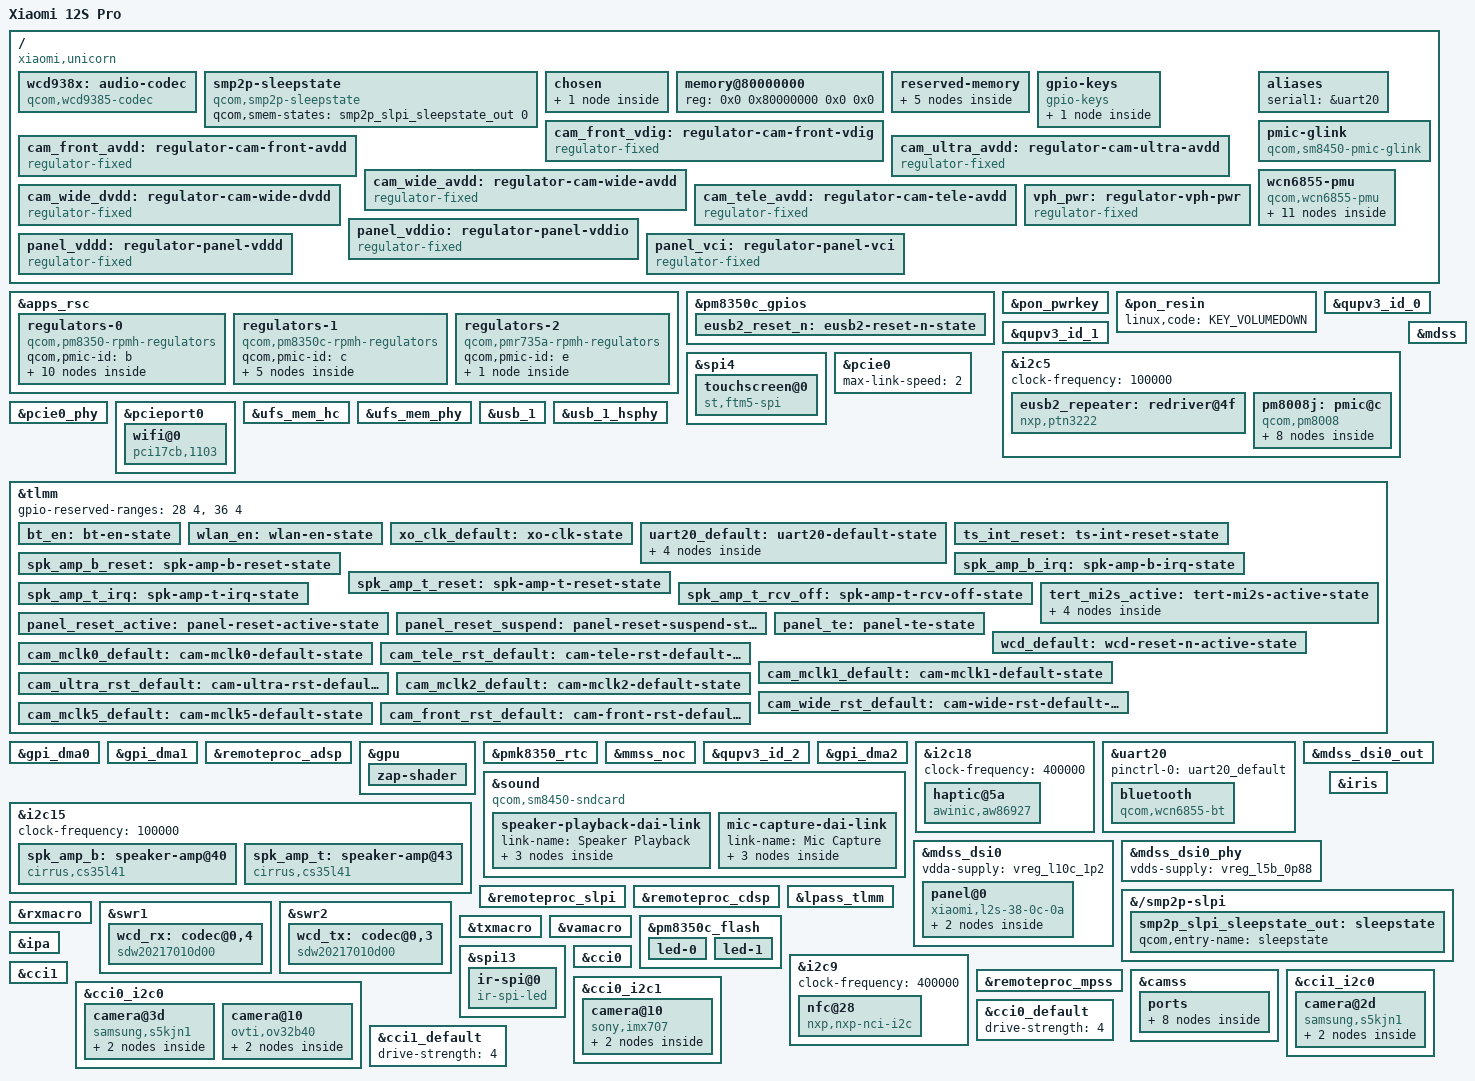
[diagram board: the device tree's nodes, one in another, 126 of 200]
// SPDX-License-Identifier: BSD-3-Clause
/*
 * Xiaomi 12S Pro (unicorn, 2206122SC, SM8475/cape)
 * Native mainline Linux DTS (UEFI EFI-stub + simplefb + USB gadget + UFS + Wi-Fi + Touch + Keys).
 */

/dts-v1/;

#include <dt-bindings/clock/qcom,sm8450-camcc.h>
#include <dt-bindings/firmware/qcom,scm.h>
#include <dt-bindings/media/video-interfaces.h>
#include <dt-bindings/gpio/gpio.h>
#include <dt-bindings/input/input.h>
#include <dt-bindings/leds/common.h>
#include <dt-bindings/interrupt-controller/arm-gic.h>
#include <dt-bindings/pinctrl/qcom,pmic-gpio.h>
#include <dt-bindings/regulator/qcom,rpmh-regulator.h>
#include <dt-bindings/sound/qcom,q6afe.h>
#include <dt-bindings/sound/qcom,q6dsp-lpass-ports.h>

#include "sm8475.dtsi"
#include "pm8350.dtsi"
#include "pm8350b.dtsi"
#include "pm8350c.dtsi"
#include "pm8450.dtsi"
#include "pmk8350.dtsi"
#include "pmr735a.dtsi"

/delete-node/ &adsp_mem;
/delete-node/ &rmtfs_mem;
/delete-node/ &xbl_ramdump_mem;
/delete-node/ &xbl_sc_mem;

/ {
	model = "Xiaomi 12S Pro";
	compatible = "xiaomi,unicorn", "qcom,cape-v2", "qcom,sm8475";
	chassis-type = "handset";

	wcd938x: audio-codec {
		compatible = "qcom,wcd9385-codec";

		pinctrl-0 = <&wcd_default>;
		pinctrl-names = "default";

		qcom,micbias1-microvolt = <2750000>;
		qcom,micbias2-microvolt = <2750000>;
		qcom,micbias3-microvolt = <2750000>;
		qcom,micbias4-microvolt = <2750000>;
		qcom,rx-device = <&wcd_rx>;
		qcom,tx-device = <&wcd_tx>;

		reset-gpios = <&tlmm 43 GPIO_ACTIVE_LOW>;

		vdd-buck-supply = <&vreg_s10b_1p8>;
		vdd-rxtx-supply = <&vreg_s10b_1p8>;
		vdd-io-supply = <&vreg_s10b_1p8>;
		vdd-mic-bias-supply = <&vreg_bob>;

		#sound-dai-cells = <1>;
	};

	smp2p-sleepstate {
		compatible = "qcom,smp2p-sleepstate";
		qcom,smem-states = <&smp2p_slpi_sleepstate_out 0>;
	};

	chosen {
		#address-cells = <2>;
		#size-cells = <2>;
		ranges;

		/* Continuous-splash / UEFI GOP framebuffer at 0xB8000000, 1440x3200 */
		framebuffer: framebuffer@b8000000 {
			compatible = "simple-framebuffer";
			reg = <0x0 0xb8000000 0x0 0x2b00000>;
			width = <1440>;
			height = <3200>;
			stride = <(1440 * 4)>;
			format = "a8r8g8b8";
			clocks = <&gcc GCC_DISP_HF_AXI_CLK>;
			power-domains = <&rpmhpd RPMHPD_MMCX>;
		};
	};

	memory@80000000 {
		device_type = "memory";
		reg = <0x0 0x80000000 0x0 0x0>;
	};

	reserved-memory {
		#address-cells = <2>;
		#size-cells = <2>;
		ranges;

		/* Remove sm8450.dtsi nodes that conflict with Unicorn's RAM/ADSP layout */
		/delete-node/ memory@80640000;
		/delete-node/ memory@85e00000;
		/delete-node/ memory@9fd00000;
		/delete-node/ memory@c0000000;

		xbl_ramdump_region@a6b80000 {
			reg = <0x0 0xa6b80000 0x0 0x280000>;
			no-map;
		};

		rmtfs_mem: memory@f8700000 {
			compatible = "qcom,rmtfs-mem";
			reg = <0x0 0xf8700000 0x0 0x280000>;
			no-map;

			qcom,client-id = <1>;
			qcom,vmid = <QCOM_SCM_VMID_MSS_MSA>;
		};

		adsp_mem: memory@9fd00000 {
			reg = <0x0 0x9fd00000 0x0 0x3100000>;
			no-map;
		};

		splash_mem: memory@b8000000 {
			reg = <0x0 0xb8000000 0x0 0x2b00000>;
			no-map;
		};

		ramoops@a7000000 {
			compatible = "ramoops";
			reg = <0x0 0xa7000000 0x0 0x400000>;
			console-size = <0x200000>;
			pmsg-size = <0x200000>;
		};
	};

	gpio-keys {
		compatible = "gpio-keys";

		key-volume-up {
			label = "Volume Up";
			gpios = <&pm8350c_gpios 6 GPIO_ACTIVE_LOW>;
			linux,code = <KEY_VOLUMEUP>;
			debounce-interval = <15>;
			linux,can-disable;
			wakeup-source;
		};
	};

	/* Front 32MP OV32B40 1.104 V VDIG, switched by TLMM 44 (vendor camera_front_vdig_ldo) */
	cam_front_vdig: regulator-cam-front-vdig {
		compatible = "regulator-fixed";
		regulator-name = "cam_front_vdig";
		regulator-min-microvolt = <1104000>;
		regulator-max-microvolt = <1104000>;
		gpio = <&tlmm 44 GPIO_ACTIVE_HIGH>;
		enable-active-high;
		startup-delay-us = <100>;
		vin-supply = <&vreg_s12b_1p25>;
	};

	/* Front 32MP OV32B40 2.8 V AVDD, switched by TLMM 64 (vendor camera_front_avdd_ldo) */
	cam_front_avdd: regulator-cam-front-avdd {
		compatible = "regulator-fixed";
		regulator-name = "cam_front_avdd";
		regulator-min-microvolt = <2800000>;
		regulator-max-microvolt = <2800000>;
		gpio = <&tlmm 64 GPIO_ACTIVE_HIGH>;
		enable-active-high;
		startup-delay-us = <100>;
		vin-supply = <&vreg_bob>;
	};

	/* Rear ultrawide 50MP S5KJN1 2.8 V AVDD, switched by TLMM 6 (vendor CAMERA_ULTRA_AVDD) */
	cam_ultra_avdd: regulator-cam-ultra-avdd {
		compatible = "regulator-fixed";
		regulator-name = "cam_ultra_avdd";
		regulator-min-microvolt = <2800000>;
		regulator-max-microvolt = <2800000>;
		gpio = <&tlmm 6 GPIO_ACTIVE_HIGH>;
		enable-active-high;
		startup-delay-us = <100>;
		vin-supply = <&vreg_bob>;
	};

	/* Rear main 50MP Sony IMX707 1.86 V AVDD2, switched by TLMM 70 (vendor camera_wide_avdd_ldo) */
	cam_wide_avdd: regulator-cam-wide-avdd {
		compatible = "regulator-fixed";
		regulator-name = "cam_wide_avdd";
		regulator-min-microvolt = <1860000>;
		regulator-max-microvolt = <1860000>;
		gpio = <&tlmm 70 GPIO_ACTIVE_HIGH>;
		enable-active-high;
		startup-delay-us = <100>;
		vin-supply = <&vreg_bob>;
	};

	/* Rear main 50MP Sony IMX707 1.25 V DVDD, switched by TLMM 2 (vendor camera_wide_dvdd_ldo) */
	cam_wide_dvdd: regulator-cam-wide-dvdd {
		compatible = "regulator-fixed";
		regulator-name = "cam_wide_dvdd";
		regulator-min-microvolt = <1250000>;
		regulator-max-microvolt = <1250000>;
		gpio = <&tlmm 2 GPIO_ACTIVE_HIGH>;
		enable-active-high;
		startup-delay-us = <100>;
		vin-supply = <&vreg_s12b_1p25>;
	};

	/* Rear telephoto 50MP S5KJN1 2.8 V AVDD, switched by TLMM 71 (vendor CAMERA_TELE_AVDD) */
	cam_tele_avdd: regulator-cam-tele-avdd {
		compatible = "regulator-fixed";
		regulator-name = "cam_tele_avdd";
		regulator-min-microvolt = <2800000>;
		regulator-max-microvolt = <2800000>;
		gpio = <&tlmm 71 GPIO_ACTIVE_HIGH>;
		enable-active-high;
		startup-delay-us = <100>;
		vin-supply = <&vreg_bob>;
	};

	vph_pwr: regulator-vph-pwr {
		compatible = "regulator-fixed";
		regulator-name = "vph_pwr";
		regulator-min-microvolt = <3700000>;
		regulator-max-microvolt = <3700000>;
		regulator-always-on;
		regulator-boot-on;
	};

	aliases {
		serial1 = &uart20;
	};

	pmic-glink {
		compatible = "qcom,sm8450-pmic-glink", "qcom,pmic-glink";
		#address-cells = <1>;
		#size-cells = <0>;
	};

	/* QCA6490 / WCN6855 PMU: WLAN_EN=80, BT_EN=81, SW_CTRL=82, XO_CLK=204 */
	wcn6855-pmu {
		compatible = "qcom,wcn6855-pmu";

		pinctrl-0 = <&bt_en>, <&wlan_en>, <&xo_clk_default>;
		pinctrl-names = "default";

		wlan-enable-gpios = <&tlmm 80 GPIO_ACTIVE_HIGH>;
		bt-enable-gpios = <&tlmm 81 GPIO_ACTIVE_HIGH>;
		swctrl-gpios = <&tlmm 82 GPIO_ACTIVE_HIGH>;
		xo-clk-gpios = <&tlmm 204 GPIO_ACTIVE_HIGH>;

		vddio-supply = <&vreg_s10b_1p8>;
		vddaon-supply = <&vreg_s11b_0p95>;
		vddpmu-supply = <&vreg_s12b_1p25>;
		vddpmumx-supply = <&vreg_s2e_0p5>;
		vddpmucx-supply = <&vreg_s11b_0p95>;
		vddrfa0p95-supply = <&vreg_s11b_0p95>;
		vddrfa1p3-supply = <&vreg_s12b_1p25>;
		vddrfa1p9-supply = <&vreg_s1c_1p86>;
		vddpcie1p3-supply = <&vreg_s12b_1p25>;
		vddpcie1p9-supply = <&vreg_s1c_1p86>;

		regulators {
			vreg_pmu_rfa_cmn_0p8: ldo0 {
				regulator-name = "vreg_pmu_rfa_cmn_0p8";
			};

			vreg_pmu_aon_0p8: ldo1 {
				regulator-name = "vreg_pmu_aon_0p8";
			};

			vreg_pmu_wlcx_0p8: ldo2 {
				regulator-name = "vreg_pmu_wlcx_0p8";
			};

			vreg_pmu_wlmx_0p8: ldo3 {
				regulator-name = "vreg_pmu_wlmx_0p8";
			};

			vreg_pmu_btcmx_0p8: ldo4 {
				regulator-name = "vreg_pmu_btcmx_0p8";
			};

			vreg_pmu_pcie_1p8: ldo5 {
				regulator-name = "vreg_pmu_pcie_1p8";
			};

			vreg_pmu_pcie_0p9: ldo6 {
				regulator-name = "vreg_pmu_pcie_0p9";
			};

			vreg_pmu_rfa_0p8: ldo7 {
				regulator-name = "vreg_pmu_rfa_0p8";
			};

			vreg_pmu_rfa_1p2: ldo8 {
				regulator-name = "vreg_pmu_rfa_1p2";
			};

			vreg_pmu_rfa_1p7: ldo9 {
				regulator-name = "vreg_pmu_rfa_1p7";
			};
		};
	};
};

&apps_rsc {
	regulators-0 {
		compatible = "qcom,pm8350-rpmh-regulators";
		qcom,pmic-id = "b";

		vreg_s10b_1p8: smps10 {
			regulator-name = "vreg_s10b_1p8";
			regulator-min-microvolt = <1800000>;
			regulator-max-microvolt = <1800000>;
		};

		vreg_s11b_0p95: smps11 {
			regulator-name = "vreg_s11b_0p95";
			regulator-min-microvolt = <952000>;
			regulator-max-microvolt = <1170000>;
		};

		vreg_s12b_1p25: smps12 {
			regulator-name = "vreg_s12b_1p25";
			regulator-min-microvolt = <1350000>;
			regulator-max-microvolt = <2040000>;
		};

		vreg_l1b_0p91: ldo1 {
			regulator-name = "vreg_l1b_0p91";
			regulator-min-microvolt = <912000>;
			regulator-max-microvolt = <920000>;
			regulator-initial-mode = <RPMH_REGULATOR_MODE_HPM>;
		};

		vreg_l2b_3p07: ldo2 {
			regulator-name = "vreg_l2b_3p07";
			regulator-min-microvolt = <3072000>;
			regulator-max-microvolt = <3300000>;
			regulator-initial-mode = <RPMH_REGULATOR_MODE_HPM>;
		};

		vreg_l3b_0p9: ldo3 {
			regulator-name = "vreg_l3b_0p9";
			regulator-min-microvolt = <904000>;
			regulator-max-microvolt = <970000>;
			regulator-initial-mode = <RPMH_REGULATOR_MODE_HPM>;
		};

		vreg_l5b_0p88: ldo5 {
			regulator-name = "vreg_l5b_0p88";
			regulator-min-microvolt = <880000>;
			regulator-max-microvolt = <958000>;
			regulator-initial-mode = <RPMH_REGULATOR_MODE_HPM>;
		};

		vreg_l6b_1p2: ldo6 {
			regulator-name = "vreg_l6b_1p2";
			regulator-min-microvolt = <1200000>;
			regulator-max-microvolt = <1216000>;
			regulator-initial-mode = <RPMH_REGULATOR_MODE_HPM>;
		};

		vreg_l7b_2p5: ldo7 {
			regulator-name = "vreg_l7b_2p5";
			regulator-min-microvolt = <2504000>;
			regulator-max-microvolt = <3544000>;
			regulator-initial-mode = <RPMH_REGULATOR_MODE_HPM>;
		};

		vreg_l9b_1p2: ldo9 {
			regulator-name = "vreg_l9b_1p2";
			regulator-min-microvolt = <1200000>;
			regulator-max-microvolt = <1304000>;
			regulator-initial-mode = <RPMH_REGULATOR_MODE_HPM>;
		};
	};

	regulators-1 {
		compatible = "qcom,pm8350c-rpmh-regulators";
		qcom,pmic-id = "c";

		/* All entries verified present in live unicorn cmd-db */
		vreg_bob: bob {
			regulator-name = "vreg_bob";
			regulator-min-microvolt = <3008000>;
			regulator-max-microvolt = <3960000>;
			regulator-initial-mode = <RPMH_REGULATOR_MODE_AUTO>;
		};

		vreg_s1c_1p86: smps1 {
			regulator-name = "vreg_s1c_1p86";
			regulator-min-microvolt = <1888000>;
			regulator-max-microvolt = <2016000>;
		};

		vreg_l2c_1p8: ldo2 {
			regulator-name = "vreg_l2c_1p8";
			regulator-min-microvolt = <1800000>;
			regulator-max-microvolt = <1984000>;
			regulator-initial-mode = <RPMH_REGULATOR_MODE_HPM>;
		};

		/* Unicorn stock DTB uses pm8350c ldo9 at 3.224 V for FTM5 avdd */
		vreg_l9c_2p96: ldo9 {
			regulator-name = "vreg_l9c_2p96";
			regulator-min-microvolt = <3224000>;
			regulator-max-microvolt = <3224000>;
			regulator-initial-mode = <RPMH_REGULATOR_MODE_HPM>;
		};

		vreg_l10c_1p2: ldo10 {
			regulator-name = "vreg_l10c_1p2";
			regulator-min-microvolt = <1200000>;
			regulator-max-microvolt = <1304000>;
			regulator-initial-mode = <RPMH_REGULATOR_MODE_HPM>;
		};
	};

	regulators-2 {
		compatible = "qcom,pmr735a-rpmh-regulators";
		qcom,pmic-id = "e";

		/* smpe2 verified present in live unicorn cmd-db */
		vreg_s2e_0p5: smps2 {
			regulator-name = "vreg_s2e_0p5";
			regulator-min-microvolt = <1012000>;
			regulator-max-microvolt = <1040000>;
		};
	};
};

&pm8350c_gpios {
	eusb2_reset_n: eusb2-reset-n-state {
		pins = "gpio7";
		function = PMIC_GPIO_FUNC_NORMAL;
		power-source = <1>;
		qcom,drive-strength = <PMIC_GPIO_STRENGTH_MED>;
		bias-disable;
		output-enable;
	};
};

&pon_pwrkey {
	status = "okay";
};

&pon_resin {
	linux,code = <KEY_VOLUMEDOWN>;
	status = "okay";
};

&qupv3_id_0 {
	status = "okay";
};

&qupv3_id_1 {
	status = "okay";
};

&i2c5 {
	clock-frequency = <100000>;
	status = "okay";

	eusb2_repeater: redriver@4f {
		compatible = "nxp,ptn3222";
		reg = <0x4f>;
		#phy-cells = <0>;

		vdd3v3-supply = <&vreg_l2b_3p07>;
		vdd1v8-supply = <&vreg_s10b_1p8>;

		reset-gpios = <&pm8350c_gpios 7 GPIO_ACTIVE_LOW>;
		pinctrl-0 = <&eusb2_reset_n>;
		pinctrl-names = "default";
	};
};

&spi4 {
	status = "okay";

	touchscreen@0 {
		compatible = "st,ftm5-spi";
		reg = <0>;
		spi-max-frequency = <12000000>;

		interrupts-extended = <&tlmm 21 IRQ_TYPE_LEVEL_LOW>;
		reset-gpios = <&tlmm 20 GPIO_ACTIVE_LOW>;

		vdd-supply = <&vreg_l2c_1p8>;
		avdd-supply = <&vreg_l9c_2p96>;

		/* 10x unicorn 1440x3200 panel resolution */
		touchscreen-size-x = <14400>;
		touchscreen-size-y = <32000>;

		pinctrl-0 = <&ts_int_reset>;
		pinctrl-names = "default";
	};
};

&pcie0 {
	max-link-speed = <2>;
	status = "okay";
};

&pcie0_phy {
	vdda-phy-supply = <&vreg_l5b_0p88>;
	vdda-pll-supply = <&vreg_l10c_1p2>;
	status = "okay";
};

&pcieport0 {
	wifi@0 {
		compatible = "pci17cb,1103";
		reg = <0x10000 0x0 0x0 0x0 0x0>;

		/* unicorn board-2.bin uses the default entry without variant suffix */
		vddrfacmn-supply = <&vreg_pmu_rfa_cmn_0p8>;
		vddaon-supply = <&vreg_pmu_aon_0p8>;
		vddwlcx-supply = <&vreg_pmu_wlcx_0p8>;
		vddwlmx-supply = <&vreg_pmu_wlmx_0p8>;
		vddpcie1p8-supply = <&vreg_pmu_pcie_1p8>;
		vddpcie0p9-supply = <&vreg_pmu_pcie_0p9>;
		vddrfa0p8-supply = <&vreg_pmu_rfa_0p8>;
		vddrfa1p2-supply = <&vreg_pmu_rfa_1p2>;
		vddrfa1p8-supply = <&vreg_pmu_rfa_1p7>;
	};
};

&ufs_mem_hc {
	reset-gpios = <&tlmm 210 GPIO_ACTIVE_LOW>;
	lanes-per-direction = <2>;

	vcc-supply = <&vreg_l7b_2p5>;
	vcc-max-microamp = <1100000>;
	vccq-supply = <&vreg_l9b_1p2>;
	vccq-max-microamp = <1200000>;

	status = "okay";
};

&ufs_mem_phy {
	vdda-phy-supply = <&vreg_l5b_0p88>;
	vdda-pll-supply = <&vreg_l10c_1p2>;
	status = "okay";
};

&usb_1 {
	dr_mode = "peripheral";
	maximum-speed = "high-speed";
	qcom,select-utmi-as-pipe-clk;

	phys = <&usb_1_hsphy>;
	phy-names = "usb2-phy";

	status = "okay";
};

&usb_1_hsphy {
	vdd-supply = <&vreg_l5b_0p88>;
	vdda12-supply = <&vreg_l10c_1p2>;

	phys = <&eusb2_repeater>;

	status = "okay";
};

&tlmm {
	/* Secure-world owned, per qcom,gpios-reserved in unicorn stock DTB */
	gpio-reserved-ranges = <28 4>, <36 4>;

	bt_en: bt-en-state {
		pins = "gpio81";
		function = "gpio";
		drive-strength = <16>;
		output-low;
		bias-pull-down;
	};

	wlan_en: wlan-en-state {
		pins = "gpio80";
		function = "gpio";
		drive-strength = <16>;
		output-low;
		bias-pull-down;
	};

	xo_clk_default: xo-clk-state {
		pins = "gpio204";
		function = "gpio";
		drive-strength = <16>;
		output-low;
		bias-pull-down;
	};

	uart20_default: uart20-default-state {
		cts-pins {
			pins = "gpio76";
			function = "qup20";
			drive-strength = <2>;
			bias-disable;
		};

		rts-pins {
			pins = "gpio77";
			function = "qup20";
			drive-strength = <2>;
			bias-pull-down;
		};

		tx-pins {
			pins = "gpio78";
			function = "qup20";
			drive-strength = <2>;
			bias-pull-up;
		};

		rx-pins {
			pins = "gpio79";
			function = "qup20";
			drive-strength = <2>;
			bias-disable;
		};
	};

	ts_int_reset: ts-int-reset-state {
		pins = "gpio20", "gpio21";
		function = "gpio";
		drive-strength = <8>;
		bias-pull-up;
	};
};

&gpi_dma0 {
	status = "okay";
};

&gpi_dma1 {
	status = "okay";
};

&remoteproc_adsp {
	firmware-name = "qcom/sm8475/xiaomi/unicorn/adsp.mbn";
	status = "okay";
};

&gpu {
	status = "okay";

	zap-shader {
		firmware-name = "qcom/sm8475/xiaomi/unicorn/a730_zap.mbn";
	};
};

&pmk8350_rtc {
	status = "okay";
};

/*
 * Keep ABL continuous-splash display-to-DDR bandwidth (RPMh BCM MM0/MM1)
 * active while simpledrm drives 0xB8000000: if mmss_noc probes with all
 * multimedia consumers disabled, icc_sync_state() drops MM1 to 0 at t=10s
 * and freezes the command-mode OLED panel on the last boot-console frame.
 */
&mmss_noc {
	status = "okay";
};

&qupv3_id_2 {
	status = "okay";
};

&gpi_dma2 {
	status = "okay";
};

&i2c18 {
	clock-frequency = <400000>;
	status = "okay";

	haptic@5a {
		compatible = "awinic,aw86927";
		reg = <0x5a>;
		reset-gpios = <&tlmm 89 GPIO_ACTIVE_LOW>;
		interrupts-extended = <&tlmm 90 IRQ_TYPE_EDGE_RISING>;
	};
};

&uart20 {
	pinctrl-0 = <&uart20_default>;
	pinctrl-names = "default";
	status = "okay";

	bluetooth {
		compatible = "qcom,wcn6855-bt";

		vddrfacmn-supply = <&vreg_pmu_rfa_cmn_0p8>;
		vddaon-supply = <&vreg_pmu_aon_0p8>;
		vddwlcx-supply = <&vreg_pmu_wlcx_0p8>;
		vddwlmx-supply = <&vreg_pmu_wlmx_0p8>;
		vddbtcmx-supply = <&vreg_pmu_btcmx_0p8>;
		vddrfa0p8-supply = <&vreg_pmu_rfa_0p8>;
		vddrfa1p2-supply = <&vreg_pmu_rfa_1p2>;
		vddrfa1p7-supply = <&vreg_pmu_rfa_1p7>;

		firmware-name = "unicorn/hpnv21", "unicorn/hpbtfw21.tlv";
		local-bd-address = [ ac 78 56 34 12 02 ];
	};
};

/* Stereo loudspeaker amplifiers: QUP SE15 (0x880000) -> CS35L41 @0x40 (bottom) & @0x43 (top) */
&i2c15 {
	clock-frequency = <100000>;
	status = "okay";

	spk_amp_b: speaker-amp@40 {
		compatible = "cirrus,cs35l41";
		reg = <0x40>;
		interrupts-extended = <&tlmm 117 IRQ_TYPE_LEVEL_LOW>;
		reset-gpios = <&tlmm 120 GPIO_ACTIVE_HIGH>;
		pinctrl-0 = <&spk_amp_b_reset>, <&spk_amp_b_irq>;
		pinctrl-names = "default";
		cirrus,boost-type = <0>;
		cirrus,boost-peak-milliamp = <4000>;
		cirrus,boost-ind-nanohenry = <1000>;
		cirrus,boost-cap-microfarad = <15>;
		cirrus,asp-sdout-hiz = <3>;
		cirrus,gpio2-src-select = <4>;
		cirrus,gpio2-output-enable;
		cirrus,subsystem-id = "unicorn";
		sound-name-prefix = "B";
		#sound-dai-cells = <1>;
	};

	spk_amp_t: speaker-amp@43 {
		compatible = "cirrus,cs35l41";
		reg = <0x43>;
		interrupts-extended = <&tlmm 88 IRQ_TYPE_LEVEL_LOW>;
		reset-gpios = <&tlmm 1 GPIO_ACTIVE_HIGH>;
		pinctrl-0 = <&spk_amp_t_reset>, <&spk_amp_t_irq>, <&spk_amp_t_rcv_off>;
		pinctrl-names = "default";
		cirrus,boost-type = <0>;
		cirrus,boost-peak-milliamp = <4000>;
		cirrus,boost-ind-nanohenry = <1000>;
		cirrus,boost-cap-microfarad = <15>;
		cirrus,asp-sdout-hiz = <3>;
		cirrus,gpio2-src-select = <4>;
		cirrus,gpio2-output-enable;
		cirrus,subsystem-id = "unicorn";
		sound-name-prefix = "T";
		#sound-dai-cells = <1>;
	};
};

&sound {
	compatible = "qcom,sm8450-sndcard";
	model = "XIAOMI-UNICORN";

	pinctrl-0 = <&tert_mi2s_active>;
	pinctrl-names = "default";

	clocks = <&q6prmcc LPASS_CLK_ID_TER_TDM_IBIT LPASS_CLK_ATTRIBUTE_INVERT_COUPLE_NO>;
	clock-names = "tertiary-mi2s";

	audio-routing = "AMIC1", "MIC BIAS1",
			"AMIC5", "MIC BIAS4",
			"TX SWR_INPUT0", "ADC1_OUTPUT",
			"TX SWR_INPUT1", "ADC4_OUTPUT";

	speaker-playback-dai-link {
		link-name = "Speaker Playback";

		cpu {
			sound-dai = <&q6apmbedai TERTIARY_TDM_RX_0>;
		};

		codec {
			sound-dai = <&spk_amp_t 0>, <&spk_amp_b 0>;
		};

		platform {
			sound-dai = <&q6apm>;
		};
	};

	mic-capture-dai-link {
		link-name = "Mic Capture";

		cpu {
			sound-dai = <&q6apmbedai TX_CODEC_DMA_TX_3>;
		};

		codec {
			sound-dai = <&wcd938x 1>, <&swr2 0>, <&txmacro 0>;
		};

		platform {
			sound-dai = <&q6apm>;
		};
	};
};

&tlmm {
	spk_amp_b_reset: spk-amp-b-reset-state {
		pins = "gpio120";
		function = "gpio";
		drive-strength = <16>;
		bias-disable;
	};

	spk_amp_b_irq: spk-amp-b-irq-state {
		pins = "gpio117";
		function = "gpio";
		drive-strength = <2>;
		bias-pull-up;
	};

	spk_amp_t_reset: spk-amp-t-reset-state {
		pins = "gpio1";
		function = "gpio";
		drive-strength = <16>;
		bias-disable;
	};

	spk_amp_t_irq: spk-amp-t-irq-state {
		pins = "gpio88";
		function = "gpio";
		drive-strength = <2>;
		bias-pull-up;
	};

	spk_amp_t_rcv_off: spk-amp-t-rcv-off-state {
		pins = "gpio52";
		function = "gpio";
		drive-strength = <2>;
		bias-disable;
		output-low;
	};

	tert_mi2s_active: tert-mi2s-active-state {
		sck-pins {
			pins = "gpio121";
			function = "mi2s2_sck";
			drive-strength = <8>;
			bias-disable;
		};

		data0-pins {
			pins = "gpio122";
			function = "mi2s2_data0";
			drive-strength = <8>;
			bias-disable;
		};

		ws-pins {
			pins = "gpio123";
			function = "mi2s2_ws";
			drive-strength = <8>;
			bias-disable;
		};

		data1-pins {
			pins = "gpio124";
			function = "mi2s2_data1";
			drive-strength = <8>;
			bias-disable;
		};
	};
};

/ {
	panel_vddio: regulator-panel-vddio {
		compatible = "regulator-fixed";
		regulator-name = "display_panel_vddio";
		regulator-min-microvolt = <1800000>;
		regulator-max-microvolt = <1800000>;
		gpio = <&tlmm 74 GPIO_ACTIVE_HIGH>;
		enable-active-high;
		regulator-boot-on;
	};

	panel_vddd: regulator-panel-vddd {
		compatible = "regulator-fixed";
		regulator-name = "display_panel_vddd";
		regulator-min-microvolt = <1500000>;
		regulator-max-microvolt = <1500000>;
		gpio = <&tlmm 25 GPIO_ACTIVE_HIGH>;
		enable-active-high;
		regulator-boot-on;
	};

	panel_vci: regulator-panel-vci {
		compatible = "regulator-fixed";
		regulator-name = "display_panel_vci";
		regulator-min-microvolt = <3000000>;
		regulator-max-microvolt = <3000000>;
		gpio = <&tlmm 75 GPIO_ACTIVE_HIGH>;
		enable-active-high;
		regulator-boot-on;
	};
};

&mdss {
	status = "okay";
};

&mdss_dsi0 {
	vdda-supply = <&vreg_l10c_1p2>;
	status = "okay";

	panel@0 {
		compatible = "xiaomi,l2s-38-0c-0a";
		reg = <0>;

		reset-gpios = <&tlmm 0 GPIO_ACTIVE_LOW>;
		vddio-supply = <&panel_vddio>;
		vddd-supply = <&panel_vddd>;
		vci-supply = <&panel_vci>;

		pinctrl-0 = <&panel_reset_active>, <&panel_te>;
		pinctrl-1 = <&panel_reset_suspend>, <&panel_te>;
		pinctrl-names = "default", "sleep";

		port {
			panel_in: endpoint {
				remote-endpoint = <&mdss_dsi0_out>;
			};
		};
	};
};

&mdss_dsi0_out {
	data-lanes = <0 1 2 3>;
	remote-endpoint = <&panel_in>;
};

&mdss_dsi0_phy {
	vdds-supply = <&vreg_l5b_0p88>;
	status = "okay";
};

&tlmm {
	panel_reset_active: panel-reset-active-state {
		pins = "gpio0";
		function = "gpio";
		drive-strength = <8>;
		bias-disable;
	};

	panel_reset_suspend: panel-reset-suspend-state {
		pins = "gpio0";
		function = "gpio";
		drive-strength = <2>;
		bias-pull-down;
	};

	panel_te: panel-te-state {
		pins = "gpio86";
		function = "mdp_vsync";
		drive-strength = <2>;
		bias-pull-down;
	};
};


/* === Wave 2 Hardware Bring-up === */

/* Qualcomm IRIS2 Hardware Video Decoder (H.264/HEVC/VP9 4K60) */
&iris {
	firmware-name = "qcom/sm8475/xiaomi/unicorn/vpu20_4v.mbn";
	status = "okay";
};

/* Sensor Low Power Island DSP (SLPI) + AP wake/sleep state */
&remoteproc_slpi {
	firmware-name = "qcom/sm8475/xiaomi/unicorn/slpi.mbn";
	status = "okay";
};

&{/smp2p-slpi} {
	smp2p_slpi_sleepstate_out: sleepstate {
		qcom,entry-name = "sleepstate";
		#qcom,smem-state-cells = <1>;
	};
};

/* Hexagon Compute/AI DSP (CDSP) */
&remoteproc_cdsp {
	firmware-name = "qcom/sm8475/xiaomi/unicorn/cdsp.mbn";
	status = "okay";
};

/* Built-in Dual Microphones (WCD9385 over SoundWire + LPASS TX/RX/VA Macros) */
&lpass_tlmm {
	status = "okay";
};

&rxmacro {
	status = "okay";
};

&swr1 {
	status = "okay";

	wcd_rx: codec@0,4 {
		compatible = "sdw20217010d00";
		reg = <0 4>;
		qcom,rx-port-mapping = <1 2 3 4 5>;
	};
};

&swr2 {
	status = "okay";

	wcd_tx: codec@0,3 {
		compatible = "sdw20217010d00";
		reg = <0 3>;
		qcom,tx-port-mapping = <1 1 2 3>;
	};
};

&txmacro {
	status = "okay";
};

&vamacro {
	status = "okay";
};

/* Rear Dual-LED Camera Flashlight / Torch (PM8350C Flash) */
&pm8350c_flash {
	status = "okay";

	led-0 {
		function = LED_FUNCTION_FLASH;
		color = <LED_COLOR_ID_WHITE>;
		led-sources = <1>, <4>;
		led-max-microamp = <500000>;
		flash-max-microamp = <1500000>;
		flash-max-timeout-us = <1280000>;
	};

	led-1 {
		function = LED_FUNCTION_FLASH;
		color = <LED_COLOR_ID_AMBER>;
		led-sources = <2>, <3>;
		led-max-microamp = <500000>;
		flash-max-microamp = <1500000>;
		flash-max-timeout-us = <1280000>;
	};
};

/* NXP SN110T NFC Controller on QUP SE9 I2C (@0x28) */
&i2c9 {
	clock-frequency = <400000>;
	status = "okay";

	nfc@28 {
		compatible = "nxp,nxp-nci-i2c";
		reg = <0x28>;
		enable-gpios = <&tlmm 34 GPIO_ACTIVE_HIGH>;
		firmware-gpios = <&tlmm 45 GPIO_ACTIVE_HIGH>;
		interrupts-extended = <&tlmm 46 IRQ_TYPE_EDGE_RISING>;
	};
};

/* Xiaomi Infrared Blaster on QUP SE13 SPI (ir-spi-led -> /dev/lirc0) */
&spi13 {
	status = "okay";

	ir-spi@0 {
		compatible = "ir-spi-led";
		reg = <0>;
		spi-max-frequency = <19200000>;
	};
};

&tlmm {
	wcd_default: wcd-reset-n-active-state {
		pins = "gpio43";
		function = "gpio";
		drive-strength = <16>;
		bias-disable;
		output-low;
	};
};


/* === Wave 3 Hardware Bring-up: 5G Modem + IPA v5.1 + CAMSS + PM8008 + 50MP S5KJN1 === */

&ipa {
	qcom,gsi-loader = "self";
	memory-region = <&ipa_gsi_mem>;
	firmware-name = "qcom/sm8475/xiaomi/unicorn/ipa_fws.mbn";
	status = "okay";
};

&remoteproc_mpss {
	firmware-name = "qcom/sm8475/xiaomi/unicorn/modem.mbn";
	status = "okay";
};

/* Camera PMIC PM8008J on QUP SE5 I2C (@0x0c core / @0x0d regulators, reset GPIO 11) */
&i2c5 {
	pm8008j: pmic@c {
		compatible = "qcom,pm8008";
		reg = <0x0c>;

		reset-gpios = <&tlmm 11 GPIO_ACTIVE_LOW>;

		vdd-l1-l2-supply = <&vreg_s12b_1p25>;
		vdd-l3-l4-supply = <&vreg_bob>;
		vdd-l5-supply = <&vreg_s1c_1p86>;
		vdd-l6-supply = <&vreg_bob>;
		vdd-l7-supply = <&vreg_bob>;

		gpio-controller;
		#gpio-cells = <2>;
		gpio-ranges = <&pm8008j 0 0 2>;

		regulators {
			pm8008j_l1: ldo1 {
				regulator-name = "pm8008j_l1";
				regulator-min-microvolt = <1056000>;
				regulator-max-microvolt = <1056000>;
			};

			pm8008j_l2: ldo2 {
				regulator-name = "pm8008j_l2";
				regulator-min-microvolt = <1056000>;
				regulator-max-microvolt = <1056000>;
			};

			pm8008j_l3: ldo3 {
				regulator-name = "pm8008j_l3";
				regulator-min-microvolt = <3300000>;
				regulator-max-microvolt = <3304000>;
			};

			pm8008j_l4: ldo4 {
				regulator-name = "pm8008j_l4";
				regulator-min-microvolt = <2808000>;
				regulator-max-microvolt = <2808000>;
			};

			pm8008j_l5: ldo5 {
				regulator-name = "pm8008j_l5";
				regulator-min-microvolt = <1800000>;
				regulator-max-microvolt = <1800000>;
			};

			pm8008j_l6: ldo6 {
				regulator-name = "pm8008j_l6";
				regulator-min-microvolt = <3104000>;
				regulator-max-microvolt = <3104000>;
			};

			pm8008j_l7: ldo7 {
				regulator-name = "pm8008j_l7";
				regulator-min-microvolt = <3104000>;
				regulator-max-microvolt = <3104000>;
			};
		};
	};
};

/* SM8450/SM8475 Camera Subsystem (CAMSS) */
&camss {
	vdda-phy-supply = <&vreg_l5b_0p88>;
	vdda-pll-supply = <&vreg_l10c_1p2>;
	status = "okay";

	ports {
		/* Rear ultrawide 50MP Samsung S5KJN1 (vendor cam-sensor2, csiphy-sd-index 0) */
		port@0 {
			csiphy0_ep: endpoint {
				clock-lanes = <7>;
				data-lanes = <0 1 2 3>;
				bus-type = <MEDIA_BUS_TYPE_CSI2_DPHY>;
				remote-endpoint = <&cam_ultra_ep>;
			};
		};

		/* Rear main 50MP Sony IMX707 (vendor cam-sensor0, csiphy-sd-index 2, 3-trio C-PHY) */
		port@2 {
			csiphy2_ep: endpoint {
				data-lanes = <0 1 2>;
				bus-type = <MEDIA_BUS_TYPE_CSI2_CPHY>;
				remote-endpoint = <&cam_wide_ep>;
			};
		};

		/* Front 32MP OmniVision OV32B40 (vendor cam-sensor1, csiphy-sd-index 3, 4-lane D-PHY) */
		port@3 {
			csiphy3_ep: endpoint {
				clock-lanes = <7>;
				data-lanes = <0 1 2 3>;
				bus-type = <MEDIA_BUS_TYPE_CSI2_DPHY>;
				remote-endpoint = <&cam_front_ep>;
			};
		};

		/* Rear telephoto 50MP Samsung S5KJN1 (vendor cam-sensor3, csiphy-sd-index 1) */
		port@1 {
			csiphy1_ep: endpoint {
				clock-lanes = <7>;
				data-lanes = <0 1 2 3>;
				bus-type = <MEDIA_BUS_TYPE_CSI2_DPHY>;
				remote-endpoint = <&cam_tele_ep>;
			};
		};
	};
};

&cci0 {
	status = "okay";
};

&cci1 {
	status = "okay";
};

&cci1_i2c0 {
	/*
	 * Rear telephoto 50MP Samsung S5KJN1 (vendor cam-sensor3):
	 * CCI1 master 0, 7-bit I2C addr 0x2d (8-bit 0x5a), MCLK0 (TLMM 100),
	 * reset TLMM 128, AVDD TLMM 71 (2.8 V), DVDD PM8008J L1 (1.056 V),
	 * VIO PM8008J L5 (1.8 V), VAF PM8008J L4 (2.808 V), CSIPHY 1.
	 */
	camera@2d {
		compatible = "samsung,s5kjn1";
		reg = <0x2d>;

		power-domains = <&camcc TITAN_TOP_GDSC>;
		clocks = <&camcc CAM_CC_MCLK0_CLK>;
		assigned-clocks = <&camcc CAM_CC_MCLK0_CLK>;
		assigned-clock-rates = <24000000>;

		reset-gpios = <&tlmm 128 GPIO_ACTIVE_LOW>;
		pinctrl-0 = <&cam_mclk0_default>, <&cam_tele_rst_default>;
		pinctrl-names = "default";

		afvdd-supply = <&pm8008j_l4>;
		vdda-supply = <&cam_tele_avdd>;
		vddd-supply = <&pm8008j_l1>;
		vddio-supply = <&pm8008j_l5>;

		rotation = <90>;
		orientation = <1>;

		port {
			cam_tele_ep: endpoint {
				data-lanes = <1 2 3 4>;
				link-frequencies = /bits/ 64 <700000000>;
				remote-endpoint = <&csiphy1_ep>;
			};
		};
	};
};

&tlmm {
	cam_mclk0_default: cam-mclk0-default-state {
		pins = "gpio100";
		function = "cam_mclk";
		drive-strength = <2>;
		bias-disable;
	};

	cam_tele_rst_default: cam-tele-rst-default-state {
		pins = "gpio128";
		function = "gpio";
		drive-strength = <2>;
		bias-disable;
	};
};


/* === Wave 4: Rear Ultrawide 50MP S5KJN1 + Rear Main 50MP Sony IMX707 (3-Trio C-PHY) === */

&cci0_i2c0 {
	/*
	 * Rear ultrawide 50MP Samsung S5KJN1 (vendor cam-sensor2):
	 * CCI0 master 0, 7-bit I2C addr 0x3d (8-bit 0x7a), MCLK1 (TLMM 101),
	 * reset TLMM 24, AVDD TLMM 6 (2.8 V), DVDD PM8008J L2 (1.056 V),
	 * VIO PM8008J L5 (1.8 V), CSIPHY 0.
	 */
	camera@3d {
		compatible = "samsung,s5kjn1";
		reg = <0x3d>;

		power-domains = <&camcc TITAN_TOP_GDSC>;
		clocks = <&camcc CAM_CC_MCLK1_CLK>;
		assigned-clocks = <&camcc CAM_CC_MCLK1_CLK>;
		assigned-clock-rates = <24000000>;

		reset-gpios = <&tlmm 24 GPIO_ACTIVE_LOW>;
		pinctrl-0 = <&cam_mclk1_default>, <&cam_ultra_rst_default>;
		pinctrl-names = "default";

		afvdd-supply = <&pm8008j_l4>;
		vdda-supply = <&cam_ultra_avdd>;
		vddd-supply = <&pm8008j_l2>;
		vddio-supply = <&pm8008j_l5>;

		rotation = <90>;
		orientation = <1>;

		port {
			cam_ultra_ep: endpoint {
				data-lanes = <1 2 3 4>;
				link-frequencies = /bits/ 64 <700000000>;
				remote-endpoint = <&csiphy0_ep>;
			};
		};
	};
};

&cci0_i2c1 {
	/*
	 * Rear main 50MP Sony IMX707 (vendor cam-sensor0):
	 * CCI0 master 1, 7-bit I2C addr 0x10 (8-bit 0x20), MCLK2 (TLMM 102, 19.2 MHz),
	 * reset TLMM 126, VIO PM8008J L5 (1.8 V), VANA1 PM8008J L6 (3.104 V),
	 * VANA2 TLMM 70 (1.86 V), DVDD TLMM 2 (1.25 V), VAF PM8008J L7 (3.104 V),
	 * CSIPHY 2 (3-trio MIPI C-PHY).
	 */
	camera@10 {
		compatible = "sony,imx707";
		reg = <0x10>;

		power-domains = <&camcc TITAN_TOP_GDSC>;
		clocks = <&camcc CAM_CC_MCLK2_CLK>;
		assigned-clocks = <&camcc CAM_CC_MCLK2_CLK>;
		assigned-clock-rates = <19200000>;

		reset-gpios = <&tlmm 126 GPIO_ACTIVE_LOW>;
		pinctrl-0 = <&cam_mclk2_default>, <&cam_wide_rst_default>;
		pinctrl-names = "default";

		vddio-supply = <&pm8008j_l5>;
		vdda2-supply = <&pm8008j_l6>;
		vdda-supply = <&cam_wide_avdd>;
		vddd-supply = <&cam_wide_dvdd>;
		vaf-supply = <&pm8008j_l7>;

		firmware-name = "qcom/sm8475/xiaomi/unicorn/imx707-wide.camregs";

		rotation = <90>;
		orientation = <1>;

		port {
			cam_wide_ep: endpoint {
				bus-type = <MEDIA_BUS_TYPE_CSI2_CPHY>;
				data-lanes = <1 2 3>;
				link-frequencies = /bits/ 64 <857600000 737600000>;
				remote-endpoint = <&csiphy2_ep>;
			};
		};
	};
};

&tlmm {
	cam_mclk1_default: cam-mclk1-default-state {
		pins = "gpio101";
		function = "cam_mclk";
		drive-strength = <2>;
		bias-disable;
	};

	cam_ultra_rst_default: cam-ultra-rst-default-state {
		pins = "gpio24";
		function = "gpio";
		drive-strength = <2>;
		bias-disable;
	};

	cam_mclk2_default: cam-mclk2-default-state {
		pins = "gpio102";
		function = "cam_mclk";
		drive-strength = <6>;
		bias-disable;
	};

	cam_wide_rst_default: cam-wide-rst-default-state {
		pins = "gpio126";
		function = "gpio";
		drive-strength = <2>;
		bias-disable;
	};
};

&cci0_default {
	drive-strength = <4>;
};

&cci1_default {
	drive-strength = <4>;
};


/* === Wave 5: Front 32MP OmniVision OV32B40 Selfie Camera === */

&cci0_i2c0 {
	/*
	 * Front 32MP OmniVision OV32B40 (vendor cam-sensor1):
	 * CCI1 master 0, 7-bit I2C addr 0x10 (8-bit 0x20), MCLK5 (TLMM 105, 19.2 MHz),
	 * reset TLMM 127, AVDD TLMM 64 (2.8 V), VDIG TLMM 44 (1.104 V),
	 * VIO PM8008J L5 (1.8 V), CSIPHY 3 (4-lane MIPI D-PHY).
	 */
	camera@10 {
		compatible = "ovti,ov32b40";
		reg = <0x10>;

		power-domains = <&camcc TITAN_TOP_GDSC>;
		clocks = <&camcc CAM_CC_MCLK5_CLK>;
		assigned-clocks = <&camcc CAM_CC_MCLK5_CLK>;
		assigned-clock-rates = <19200000>;

		reset-gpios = <&tlmm 127 GPIO_ACTIVE_LOW>;
		pinctrl-0 = <&cam_mclk5_default>, <&cam_front_rst_default>;
		pinctrl-names = "default";

		vdda-supply = <&cam_front_avdd>;
		vddio-supply = <&pm8008j_l5>;
		vddd-supply = <&cam_front_vdig>;

		firmware-name = "qcom/sm8475/xiaomi/unicorn/ov32b40-front.camregs";

		rotation = <270>;
		orientation = <0>;

		port {
			cam_front_ep: endpoint {
				data-lanes = <1 2 3 4>;
				link-frequencies = /bits/ 64 <556000000>;
				remote-endpoint = <&csiphy3_ep>;
			};
		};
	};
};

&tlmm {
	cam_mclk5_default: cam-mclk5-default-state {
		pins = "gpio105";
		function = "cam_mclk";
		drive-strength = <2>;
		bias-disable;
	};

	cam_front_rst_default: cam-front-rst-default-state {
		pins = "gpio127";
		function = "gpio";
		drive-strength = <2>;
		bias-disable;
	};
};
